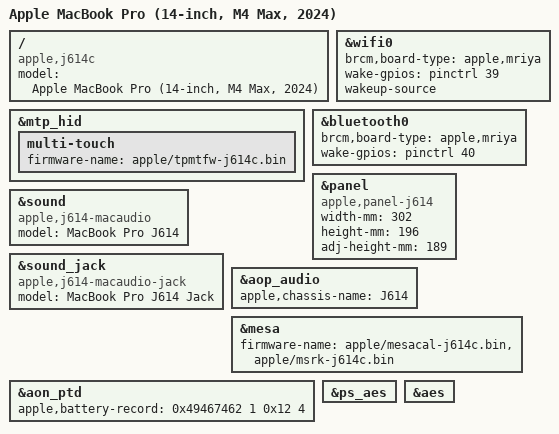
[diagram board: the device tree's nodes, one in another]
// SPDX-License-Identifier: GPL-2.0+ OR MIT
/*
 * Apple MacBook Pro (14-inch, M4 Max, 2024)
 *
 * target-type: J614c
 *
 * The J616c's T6041 wiring with the 14-inch chassis of the J614s.
 *
 * From the J614c: the speakers. macOS on a J614c reports the J614s's
 * acoustic ID 34 and six speaker records, all six amps bind on a J614c at
 * the shared J614c/J616c addresses, and the boot loader fills each amp's
 * speaker-config row from that Mac's own ADT.
 *
 * Still borrowed, with no J614c ADT in the tree: the CPU limits and
 * operating points, trackpad and keyboard wiring and panel brightness are
 * the J616c's (guessed), and the Wi-Fi island the J614s's (guessed).
 *
 * Copyright The Asahi Linux Contributors
 */

/dts-v1/;

#include "t6041.dtsi"
#include "t6041-j614-j616-j575-scaler.dtsi"
#include "t6041-j614c-j616c.dtsi"

/ {
	compatible = "apple,j614c", "apple,t6041", "apple,arm-platform";
	model = "Apple MacBook Pro (14-inch, M4 Max, 2024)";
};

&mtp_hid {
	multi-touch {
		firmware-name = "apple/tpmtfw-j614c.bin";
	};
};

&wifi0 {
	brcm,board-type = "apple,mriya";
	/* WLAN host wake (PCIe WAKE#), active high */
	wake-gpios = <&pinctrl 39 GPIO_ACTIVE_HIGH>;
	wakeup-source;
};

&bluetooth0 {
	brcm,board-type = "apple,mriya";
	/* Bluetooth host wake (PCIe WAKE#), active high */
	wake-gpios = <&pinctrl 40 GPIO_ACTIVE_HIGH>;
};

/* The J614s panel. */
&panel {
	compatible = "apple,panel-j614", "apple,panel-mini-led", "apple,panel";
	width-mm = <302>;
	height-mm = <196>;
	adj-height-mm = <189>;
};

/*
 * The J614s speakers (acoustic ID 34 on the J614c too): the same six amps,
 * slots and frame as the J616c (the boot loader copies each amp's ADT
 * speaker-config row). Playback waits for a protection lease, which
 * speakerguardd v2 takes only after compiling and self-checking this Mac's
 * own tuning; the legacy protection has no J614 profile, so without v2 the
 * amps stay at the kernel's floor.
 */
&sound {
	compatible = "apple,j614-macaudio", "apple,macaudio";
	model = "MacBook Pro J614";
};

&sound_jack {
	compatible = "apple,j614-macaudio-jack", "apple,macaudio";
	model = "MacBook Pro J614 Jack";
};

&aop_audio {
	apple,chassis-name = "J614";
};

&mesa {
	firmware-name = "apple/mesacal-j614c.bin", "apple/msrk-j614c.bin";
};

/*
 * ADT /arm-io/aon-ptd ptd_data_table: the battery record ("IFtb", layout 1,
 * slots 0x12-0x15). Only its peek aperture is read.
 */
&aon_ptd {
	apple,battery-record = <0x49467462 1 0x12 4>;
	status = "okay";
};

/* SIO AES engine, software keys only. */
&ps_aes {
	status = "okay";
};

&aes {
	status = "okay";
};
